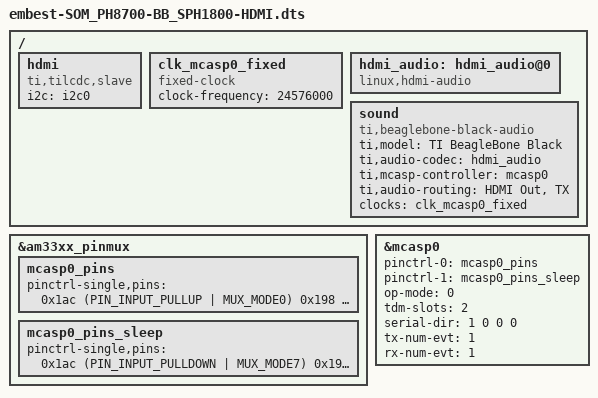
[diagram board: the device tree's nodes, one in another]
/*
 * Copyright (C) 2015 Embest Technology Co., Ltd., - http://www.embest-tech.com
 *
 * This program is free software; you can redistribute it and/or modify
 * it under the terms of the GNU General Public License version 2 as
 * published by the Free Software Foundation.
 *
 * This dts is for embest own product:
 * SOM-PH8800 + BB-SPH1800
 */
/*/dts-v1/;*/

#include "embest-SOM_PH8700-BB_SPH1800.dts"

&am33xx_pinmux {
	mcasp0_pins: mcasp0_pins {
		pinctrl-single,pins = <
			0x1ac (PIN_INPUT_PULLUP | MUX_MODE0)	/* mcasp0_ahclkx.mcasp0_ahclkx */
			0x198 (PIN_OUTPUT_PULLDOWN | MUX_MODE0)	/* MCASP0_AXR0.MCASP0_AXR0 */
			0x194 (PIN_OUTPUT_PULLUP | MUX_MODE0)	/* mcasp0_fsx.mcasp0_fsx */
			0x190 (PIN_OUTPUT_PULLDOWN | MUX_MODE0)	/* mcasp0_aclkx.mcasp0_aclkx */
		>;
	};

	mcasp0_pins_sleep: mcasp0_pins_sleep {
		pinctrl-single,pins = <
			0x1ac (PIN_INPUT_PULLDOWN | MUX_MODE7)	/* mcasp0_ahclkx.mcasp0_ahclkx */
			0x198 (PIN_INPUT_PULLDOWN | MUX_MODE7)  /* MCASP0_AXR0.MCASP0_AXR0 */
			0x194 (PIN_INPUT_PULLDOWN | MUX_MODE7)	/* mcasp0_fsx.mcasp0_fsx */
			0x190 (PIN_INPUT_PULLDOWN | MUX_MODE7)	/* mcasp0_aclkx.mcasp0_aclkx */
		>;
	};
};


&mcasp0	{
	pinctrl-names = "default", "sleep";
	pinctrl-0 = <&mcasp0_pins>;
	pinctrl-1 = <&mcasp0_pins_sleep>;
	status = "okay";
	op-mode = <0>;	/* MCASP_IIS_MODE */
	tdm-slots = <2>;
	serial-dir = <	/* 0: INACTIVE, 1: TX, 2: RX */
			1 0 0 0
		>;
	tx-num-evt = <1>;
	rx-num-evt = <1>;
};

/ {
	hdmi {
		compatible = "ti,tilcdc,slave";
		i2c = <&i2c0>;
		status = "okay";
	};

	clk_mcasp0_fixed: clk_mcasp0_fixed {
	      #clock-cells = <0>;
	      compatible = "fixed-clock";
	      clock-frequency = <24576000>;
	};

	/*clk_mcasp0: clk_mcasp0 {
	      #clock-cells = <0>;
	      compatible = "gpio-gate-clock";
	      clocks = <&clk_mcasp0_fixed>;
	      enable-gpios = <&gpio1 27 0>; 
	};*/

	hdmi_audio: hdmi_audio@0 {
	       compatible = "linux,hdmi-audio";
	       status = "okay";
	};

	sound {
		compatible = "ti,beaglebone-black-audio";
		ti,model = "TI BeagleBone Black";
		ti,audio-codec = <&hdmi_audio>;
		ti,mcasp-controller = <&mcasp0>;
		ti,audio-routing =
			"HDMI Out",	"TX";
		clocks = <&clk_mcasp0_fixed>;
		clock-names = "mclk";
	};
};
